# R7FA0E107 register map
Vendor: Renesas Electronics Corporation; Series: RA0; File version: 1.10.00
CPU: CM23 r1p0, little endian, no MPU, no FPU, VTOR, 2 interrupt priority bits, 64 interrupts
Registers are 16-bit, read-write, reset 0x0 unless marked. A register's access mark holds for its fields unless they carry their own. Offsets are from the block's base; [hi:lo] are bit positions; {n}, {i} and the like mark numbered series; 'fields as' and 'values as' point back to an identical list.

## TAU — Timer Array Unit
Base 0x400A2600
{0x0+2i} TDR{i:02} (i=0..7) — Timer Data Register {i:02}
0x02 TDR01L 8-bit (alternate view of TDR01) — Timer Data Register 01
0x03 TDR01H 8-bit (alternate view of TDR01) — Timer Data Register 01
0x06 TDR03L 8-bit (alternate view of TDR03) — Timer Data Register 03
0x07 TDR03H 8-bit (alternate view of TDR03) — Timer Data Register 03
{0x100+2i} TCR0{i} (i=0..7) ro reset 0xFFFF — Timer Counter Register 0{i}
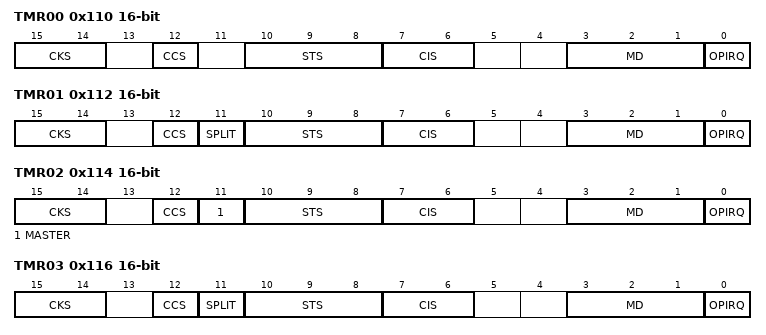
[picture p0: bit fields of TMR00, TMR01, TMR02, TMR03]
0x110 TMR00 — Timer Mode Register 00
  [15:14] CKS — Selection of Operation Clock (fMCK) of Channel n
  [12] CCS — Selection of Counter Clock (fTCLK) of Channel n
  [10:8] STS — Setting of Start Trigger or Capture Trigger of Channel n
  [7:6] CIS — Selection of TI0n Pin Input Valid Edge
  [3:1] MD — Selection of Operation Mode at Channel n
  [0] OPIRQ — Setting of Starting Count and Interrupt
0x112 TMR01 — Timer Mode Register 01
  [15:14] CKS — Selection of Operation Clock (fMCK) of Channel n
  [12] CCS — Selection of Counter Clock (fTCLK) of Channel n
  [11] SPLIT — Selection of 8 or 16-bit Timer Operation for Channels 1 and 3
  [10:8] STS — Setting of Start Trigger or Capture Trigger of Channel n
  [7:6] CIS — Selection of TI0n Pin Input Valid Edge
  [3:1] MD — Selection of Operation Mode at Channel n
  [0] OPIRQ — Setting of Starting Count and Interrupt
0x114 TMR02 — Timer Mode Register 02
  [15:14] CKS — Selection of Operation Clock (fMCK) of Channel n
  [12] CCS — Selection of Counter Clock (fTCLK) of Channel n
  [11] MASTER — Selection Between Using Channel n Independently or Simultaneously with Another Channel (as a Slave or Master)
  [10:8] STS — Setting of Start Trigger or Capture Trigger of Channel n
  [7:6] CIS — Selection of TI0n Pin Input Valid Edge
  [3:1] MD — Selection of Operation Mode at Channel n
  [0] OPIRQ — Setting of Starting Count and Interrupt
0x116 TMR03 — Timer Mode Register 03
  fields as TMR01
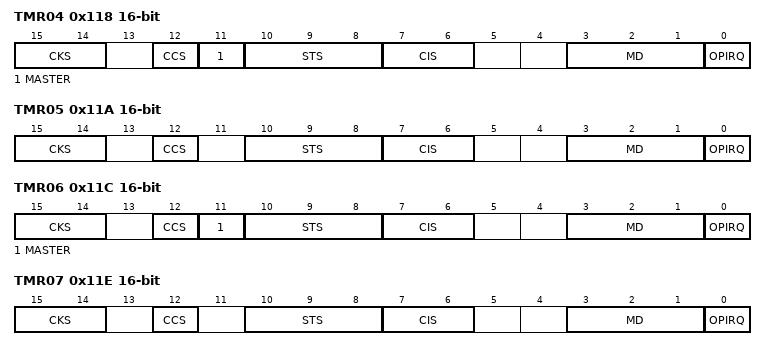
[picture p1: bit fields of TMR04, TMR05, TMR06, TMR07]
0x118 TMR04 — Timer Mode Register 04
  fields as TMR02
0x11A TMR05 — Timer Mode Register 05
  fields as TMR00
0x11C TMR06 — Timer Mode Register 06
  fields as TMR02
0x11E TMR07 — Timer Mode Register 07
  fields as TMR00
{0x120+2i} TSR0{i} (i=0..7) ro — Timer Status Register 0{i}
  [0] OVF — Counter Overflow State of Channel n
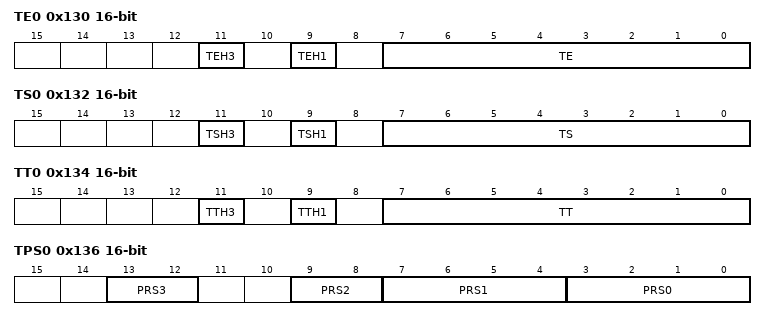
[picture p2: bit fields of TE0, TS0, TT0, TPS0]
0x130 TE0 ro — Timer Channel Enable Status Register 0
  [11] TEH3 — Indication of whether Operation of the Higher 8-bit Timer is Enabled or Stopped when Channel 3 is in the 8-bit Timer Mode
  [9] TEH1 — Indication of whether Operation of the Higher 8-bit Timer is Enabled or Stopped when Channel 1 is in the 8-bit Timer Mode
  [7:0] TE — Indication of Operation Enabled or Stopped State of Channel n
0x132 TS0 — Timer Channel Start Register 0
  [11] TSH3 — Trigger to Enable Operation (Start Operation) of the Higher 8-bit Timer when Channel 3 is in the 8-bit Timer Mode
  [9] TSH1 — Trigger to Enable Operation (Start Operation) of the Higher 8-bit Timer when Channel 1 is in the 8-bit Timer Mode
  [7:0] TS — Operation Enable (Start) Trigger of Channel n
0x134 TT0 — Timer Channel Stop Register 0
  [11] TTH3 — Trigger to Stop Operation of the Higher 8-bit Timer when Channel 3 is in the 8-bit Timer Mode
  [9] TTH1 — Trigger to Stop Operation of the Higher 8-bit Timer when Channel 1 is in the 8-bit Timer Mode
  [7:0] TT — Operation Stop Trigger of Channel n
0x136 TPS0 — Timer Clock Select Register 0
  [13:12] PRS3 — Selection of Operation Clock (CK03)
  [9:8] PRS2 — Selection of Operation Clock (CK02)
  [7:4] PRS1 — Selection of Operation Clock (CK01)
  [3:0] PRS0 — Selection of Operation Clock (CK00)
0x138 TO0 — Timer Output Register 0
  [7:0] TO — Timer Output of Channel n
0x13A TOE0 — Timer Output Enable Register 0
  [7:0] TOE — Enabling or Disabling Timer Output for Channel n
0x13C TOL0 — Timer Output Level Register 0
  [7:1] TOL — Control of Timer Output of Channel n
0x13E TOM0 — Timer Output Mode Register 0
  [7:1] TOM — Control of Timer Output Mode of Channel n
